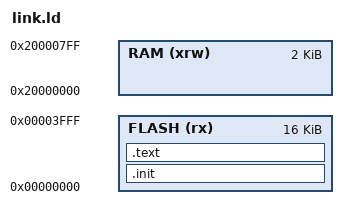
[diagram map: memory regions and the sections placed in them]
ENTRY( _start )

__stack_size = 256; # TODO

PROVIDE( _stack_size = __stack_size );

MEMORY
{
	FLASH (rx) : ORIGIN = 0x00000000, LENGTH = 16K
	RAM (xrw)  : ORIGIN = 0x20000000, LENGTH = 2K
}

SECTIONS
{
    .init :
    {
      _sinit = .;
      . = ALIGN(4);
      KEEP(*(SORT_NONE(.init)))
      . = ALIGN(4);
      _einit = .;
    } >FLASH AT>FLASH

    .text :
    {
      . = ALIGN(4);
      *(.text)
      *(.text.*)
      *(.rodata)
      *(.rodata*)
      . = ALIGN(4);
    } >FLASH AT>FLASH

    PROVIDE( _eusrstack = ORIGIN(RAM) + LENGTH(RAM));

    /DISCARD/ : {
      *(.note .note.*)
      *(.eh_frame .eh_frame.*)
      *(.comment .comment.*)
      *(.ARM.extab* .gnu.linkonce.armextab.*)
      *(.ARM.exidx*)
    }

}
